VERSION ""

NS_ :

BS_:

BU_: PPT Power_Node_1 Control_Node

BO_ 2147483654 PPTMisfireCount: 4 PPT
 SG_ totalMisfires2 : 16|16@1+ (1,0) [0|65536] "" Vector__XXX
 SG_ totalMisfires1 : 0|16@1+ (1,0) [0|65536] "" Vector__XXX

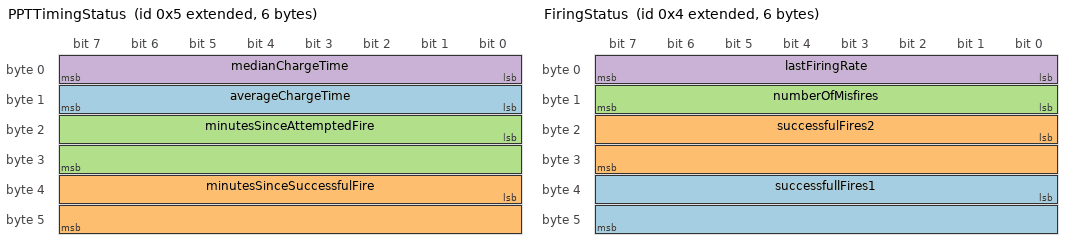
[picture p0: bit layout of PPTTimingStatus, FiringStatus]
BO_ 2147483653 PPTTimingStatus: 6 PPT
 SG_ averageChargeTime : 8|8@1+ (2,0) [0|512] "" Vector__XXX
 SG_ minutesSinceSuccessfulFire : 32|16@1+ (1,0) [0|65536] "min" Vector__XXX
 SG_ minutesSinceAttemptedFire : 16|16@1+ (1,0) [0|65536] "min" Vector__XXX
 SG_ medianChargeTime : 0|8@1+ (2,0) [0|512] "ms" Vector__XXX

BO_ 2147483652 FiringStatus: 6 Vector__XXX
 SG_ successfullFires1 : 32|16@1+ (1,0) [0|65536] "" Vector__XXX
 SG_ successfulFires2 : 16|16@1- (1,0) [0|65536] "" Vector__XXX
 SG_ numberOfMisfires : 8|8@1+ (1,0) [0|256] "" Vector__XXX
 SG_ lastFiringRate : 0|8@1+ (1,0) [0|8] "" Vector__XXX

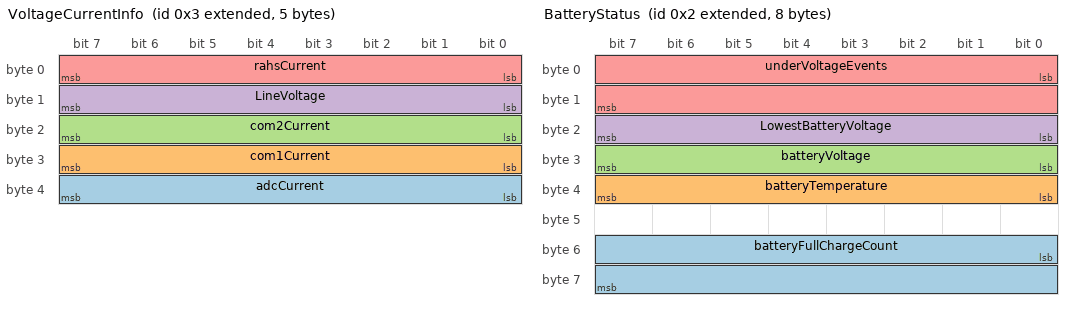
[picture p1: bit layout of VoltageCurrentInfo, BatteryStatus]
BO_ 2147483651 VoltageCurrentInfo: 5 Power_Node_1
 SG_ adcCurrent : 32|8@1+ (25,0) [0|6400] "mA" Vector__XXX
 SG_ com1Current : 24|8@1+ (1,0) [0|64] "mA" Vector__XXX
 SG_ com2Current : 16|8@1+ (25,0) [0|6400] "mA" Vector__XXX
 SG_ LineVoltage : 8|8@1+ (25,0) [0|6400] "mV" Vector__XXX
 SG_ rahsCurrent : 0|8@1+ (25,0) [0|6400] "mA" Vector__XXX

BO_ 2147483650 BatteryStatus: 8 Power_Node_1
 SG_ batteryFullChargeCount : 48|16@1- (1,0) [0|65536] "" Vector__XXX
 SG_ batteryTemperature : 32|8@1- (1.5,0) [-200|184] "C" Vector__XXX
 SG_ batteryVoltage : 24|8@1+ (25,0) [2000|84000] "mV" Vector__XXX
 SG_ LowestBatteryVoltage : 16|8@1+ (25,0) [2000|8400] "mV" Vector__XXX
 SG_ underVoltageEvents : 0|16@1+ (1,0) [0|65536] "" Vector__XXX

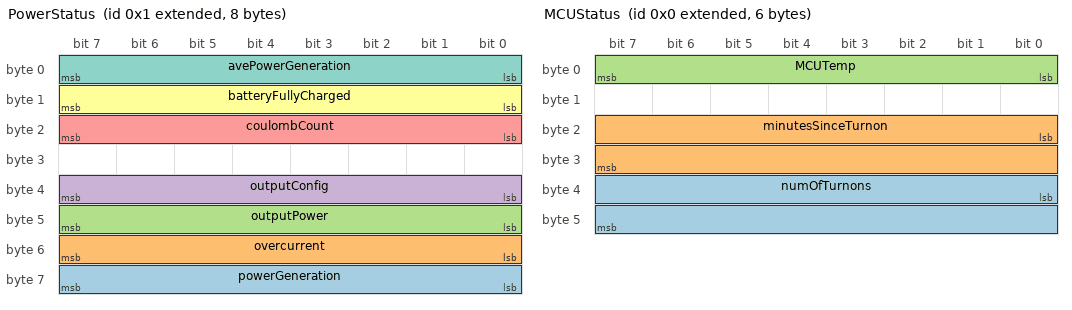
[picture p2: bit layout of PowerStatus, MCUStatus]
BO_ 2147483649 PowerStatus: 8 Power_Node_1
 SG_ powerGeneration : 56|8@1+ (150,0) [0|38400] "mW" Vector__XXX
 SG_ overcurrent : 48|8@1+ (1,0) [0|255] "bools" Vector__XXX
 SG_ outputPower : 40|8@1+ (150,0) [0|38400] "mW" Vector__XXX
 SG_ outputConfig : 32|8@1+ (1,0) [0|255] "bools" Vector__XXX
 SG_ coulombCount : 16|8@1+ (15,0) [0|3840] "mA*hr" Vector__XXX
 SG_ batteryFullyCharged : 8|8@1+ (1,0) [0|1] "Boolean" Vector__XXX
 SG_ avePowerGeneration : 0|8@1+ (100,0) [0|25600] "mW" Vector__XXX

BO_ 2147483648 MCUStatus: 6 Power_Node_1
 SG_ numOfTurnons : 32|16@1+ (1,0) [0|66536] "" Vector__XXX
 SG_ minutesSinceTurnon : 16|16@1+ (1,0) [0|66536] "min/16" Vector__XXX
 SG_ MCUTemp : 0|8@1- (1,0) [-128|127] "C" Vector__XXX

BA_DEF_  "BusType" STRING ;
BA_DEF_DEF_  "BusType" "";
BA_ "BusType" "CAN";
